# MCXN236 register map
Vendor: nxp.com; File version: 1.0
CPU: CM33 r2p0, little endian, MPU, FPU, VTOR, 3 interrupt priority bits
Registers are 32-bit, read-write, reset 0x0 unless marked. A register's access mark holds for its fields unless they carry their own. Offsets are from the block's base; [hi:lo] are bit positions; {n}, {i} and the like mark numbered series; 'fields as' and 'values as' point back to an identical list.

## FMU0 — Flash
Base 0x40043000
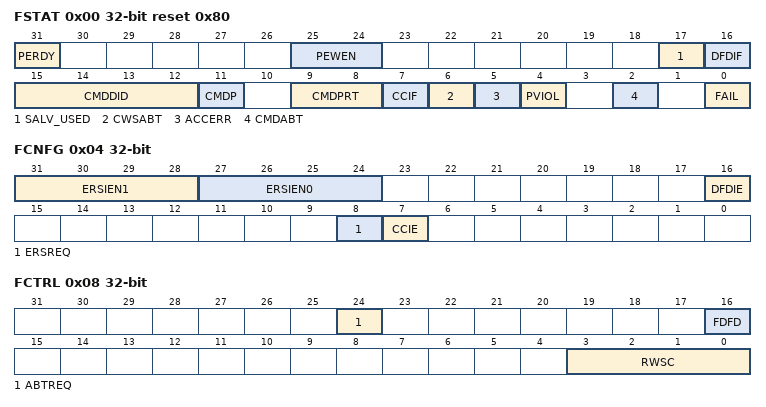
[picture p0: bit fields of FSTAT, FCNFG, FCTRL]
0x00 FSTAT reset 0x80 (reset mask 0xFFFFFFFE) — Flash Status Register
  [31] PERDY write-1-clears — Program-Erase Ready Control/Status Flag
    0=Program or sector erase command operation not stalled; 1=Program or sector erase command operation ready to execute
  [25:24] PEWEN ro — Program-Erase Write Enable Control
    0=Writes are not enabled; 1=Writes are enabled for one flash or IFR phrase (phrase programming, sector erase); 2=Writes are enabled for one flash or IFR page (page programming)
  [17] SALV_USED ro — Salvage Used for Erase operation
    0=Salvage not used during last operation; 1=Salvage used during the last erase operation
  [16] DFDIF write-1-clears — Double Bit Fault Detect Interrupt Flag
    0=Double bit fault not detected during a valid flash read access; 1=Double bit fault detected (or FCTRL[FDFD] is set) during a valid flash read access
  [15:12] CMDDID ro — Command domain ID
  [11] CMDP ro — Command protection status flag
    0=Command protection level and domain ID are stale; 1=Command protection level (CMDPRT) and domain ID (CMDDID) are set
  [9:8] CMDPRT ro — Command protection level
    0=Secure, normal access; 1=Secure, privileged access; 2=Nonsecure, normal access; 3=Nonsecure, privileged access
  [7] CCIF write-1-clears — Command Complete Interrupt Flag
    0=Flash command, initialization, or power mode recovery in progress; 1=Flash command, initialization, or power mode recovery has completed
  [6] CWSABT write-1-clears — Command Write Sequence Abort Flag
    0=Command write sequence not aborted; 1=Command write sequence aborted
  [5] ACCERR write-1-clears — Command Access Error Flag
    0=No access error detected; 1=Access error detected
  [4] PVIOL write-1-clears — Command Protection Violation Flag
    0=No protection violation detected; 1=Protection violation detected
  [2] CMDABT write-1-clears — Command Abort Flag
    0=No command abort detected; 1=Command abort detected
  [0] FAIL ro — Command Fail Flag
    0=Error not detected; 1=Error detected
0x04 FCNFG (reset mask 0xFFFFFF) — Flash Configuration Register
  [31:28] ERSIEN1 ro — Erase IFR Sector Enable - Block 1 (for dual block configs)
    0=Block 1 IFR Sector X is protected from erase by ERSSCR command; 1=Block 1 IFR Sector X is not protected from erase by ERSSCR command
  [27:24] ERSIEN0 ro — Erase IFR Sector Enable - Block 0
    0=Block 0 IFR Sector X is protected from erase by ERSSCR command; 1=Block 0 IFR Sector X is not protected from erase by ERSSCR command
  [16] DFDIE — Double Bit Fault Detect Interrupt Enable
    0=Double bit fault detect interrupt disabled; 1=Double bit fault detect interrupt enabled
  [8] ERSREQ ro — Mass Erase Request
    0=No request or request complete; 1=Request to run the Mass Erase operation
  [7] CCIE — Command Complete Interrupt Enable
    0=Command complete interrupt disabled; 1=Command complete interrupt enabled
0x08 FCTRL (reset mask 0xFFFFFFF0) — Flash Control Register
  [24] ABTREQ — Abort Request
    0=No request to abort a command write sequence; 1=Request to abort a command write sequence
  [16] FDFD — Force Double Bit Fault Detect
    0=FSTAT[DFDIF] sets only if a double bit fault is detected during a valid flash read access from the platform flash controller; 1=FSTAT[DFDIF] sets during any valid flash read access from the platform flash controller. An interrupt request is generated if the DFDIE bit is set.
  [3:0] RWSC — Read Wait-State Control
{0x10+4i} FCCOB{i} (i=0..7) — Flash Common Command Object Registers
  [31:0] CCOBn

## WUU0 — WUU
Base 0x40046000
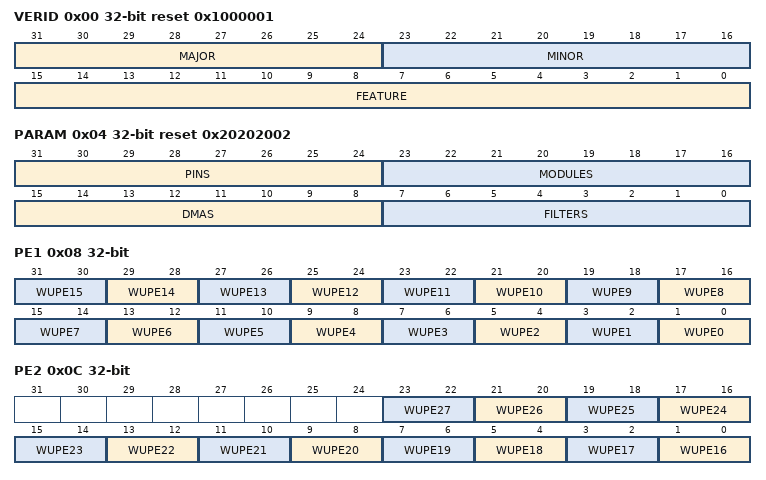
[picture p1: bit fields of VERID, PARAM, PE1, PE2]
0x00 VERID ro reset 0x1000001 — Version ID
  [31:24] MAJOR — Major Version Number
  [23:16] MINOR — Minor Version Number
  [15:0] FEATURE — Feature Specification Number
    0=STANDARD (Standard features implemented); 1=FILT_ALL_PWR (Support for DMA/Trigger generation from wake-up pins and filters enabled. Support for external pin/filter detection during all power modes enabled.)
0x04 PARAM ro reset 0x20202002 — Parameter
  [31:24] PINS — Pin Number
  [23:16] MODULES — Module Number
  [15:8] DMAS — DMA Number
  [7:0] FILTERS — Filter Number
0x08 PE1 — Pin Enable 1
  [all] fields
    0=DISABLE; 1=EN_RISE_HI (Enable (detect on rising edge or high level)); 2=EN_FALL_LO (Enable (detect on falling edge or low level)); 3=EN_ANY (Enable (detect on any edge))
  [2n+1:2n] WUPE{n} (n=0..15) — Wake-up Pin Enable for WUU_Pn
0x0C PE2 — Pin Enable 2
  [all] fields
    values as the fields of PE1
  [2n-31:2n-32] WUPE{n} (n=16..27) — Wake-up Pin Enable for WUU_Pn
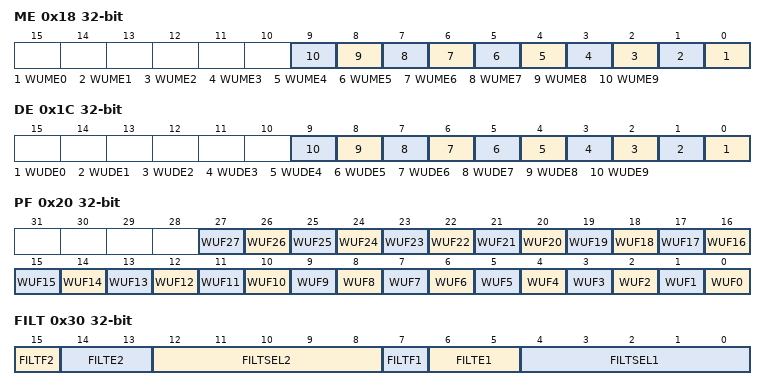
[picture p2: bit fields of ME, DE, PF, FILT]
0x18 ME — Module Interrupt Enable
  [all] fields
    0=DISABLE (Disables); 1=ENABLE (Enables)
  [n] WUME{n} (n=0..9) — Module Interrupt Wake-up Enable for Module n
0x1C DE — Module DMA/Trigger Enable
  [n] WUDE{n} (n=0..9) — DMA/Trigger Wake-up Enable for Module {n}
0x20 PF — Pin Flag
  [all] fields
    0=NO_FLAG; 1=FLAG (Yes)
  [n] WUF{n} write-1-clears (n=0..27) — Wake-up Flag for WUU_Pn
0x30 FILT — Pin Filter
  [15] FILTF2 write-1-clears — Filter 2 Flag
    0=NO_FLAG; 1=FLAG (Yes)
  [14:13] FILTE2 — Filter 2 Enable
    0=DISABLE; 1=EN_RISE_HI (Enable (Detect on rising edge or high level)); 2=EN_FALL_LO (Enable (Detect on falling edge or low level)); 3=EN_ANY (Enable (Detect on any edge))
  [12:8] FILTSEL2 — Filter 2 Pin Select
  [7] FILTF1 write-1-clears — Filter 1 Flag
    0=NO_FLAG; 1=FLAG (Yes)
  [6:5] FILTE1 — Filter 1 Enable
    values as FILTE2
  [4:0] FILTSEL1 — Filter 1 Pin Select
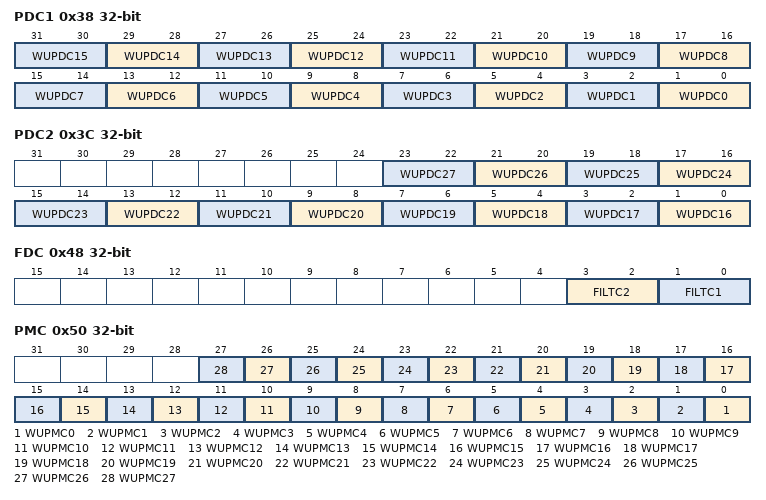
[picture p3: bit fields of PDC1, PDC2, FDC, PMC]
0x38 PDC1 — Pin DMA/Trigger Configuration 1
  [all] fields
    0=INTERRUPT; 1=DMA_REQ (DMA request); 2=TRIGGER (Trigger event)
  [2n+1:2n] WUPDC{n} (n=0..15) — Wake-up Pin Configuration for WUU_Pn
0x3C PDC2 — Pin DMA/Trigger Configuration 2
  [all] fields
    values as the fields of PDC1
  [2n-31:2n-32] WUPDC{n} (n=16..27) — Wake-up Pin Configuration for WUU_Pn
0x48 FDC — Pin Filter DMA/Trigger Configuration
  [3:2] FILTC2 — Filter Configuration for FILTn
    values as the fields of PDC1
  [1:0] FILTC1 — Filter Configuration for FILTn
    values as the fields of PDC1
0x50 PMC — Pin Mode Configuration
  [all] fields
    0=LOW_PWR_ONLY (Active only during a low-leakage mode. You can modify the corresponding fields within Pin Enable (PEn) or Pin DMA/Trigger Configuration (PDCn).); 1=ANY_PWR (Active during all power modes. Do not modify the corresponding fields within Pin Enable (PEn) or Pin DMA/Trigger Configuration (PDCn).)
  [n] WUPMC{n} (n=0..27) — Wake-up Pin Mode Configuration for WUU_Pn
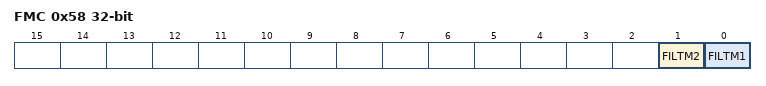
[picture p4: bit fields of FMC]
0x58 FMC — Pin Filter Mode Configuration
  [1] FILTM2 — Filter Mode for FILTn
    0=LOW_PWR_ONLY (Active only during Power Down/Deep Power Down mode); 1=ANY_PWR (Active during all power modes)
  [0] FILTM1 — Filter Mode for FILTn
    values as FILTM2
